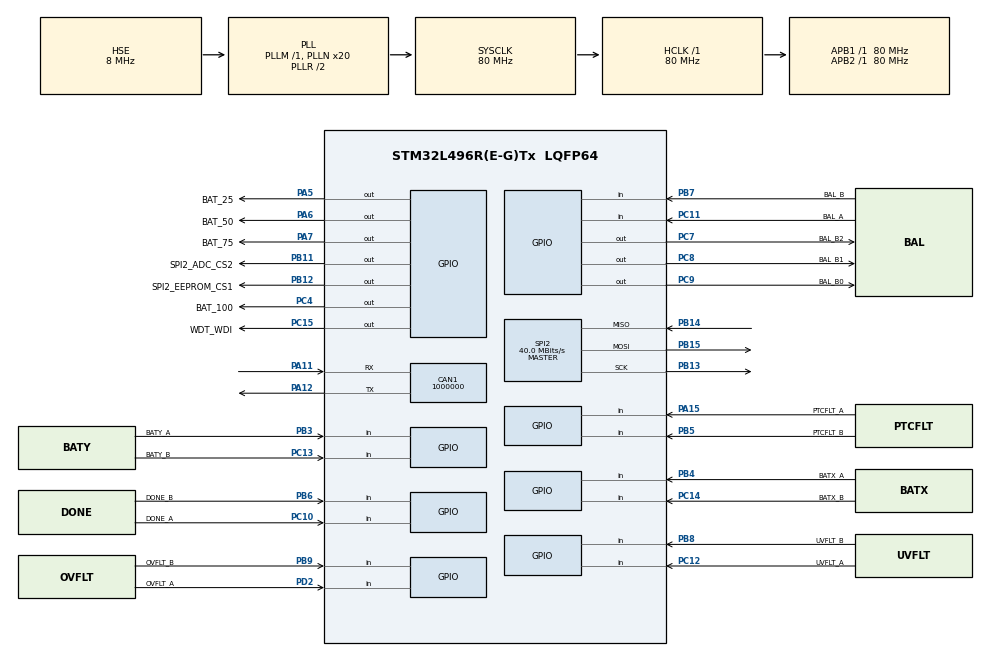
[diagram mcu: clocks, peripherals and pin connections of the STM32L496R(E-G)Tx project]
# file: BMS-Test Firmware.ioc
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CAN1.BS1=CAN_BS1_3TQ
CAN1.CalculateBaudRate=1000000
CAN1.CalculateTimeBit=1000.00
CAN1.CalculateTimeQuantum=200.0
Mcu.Family=STM32L4
Mcu.Name=STM32L496R(E-G)Tx
Mcu.Package=LQFP64
NVIC.PriorityGroup=NVIC_PRIORITYGROUP_4
PA11.Mode=CAN_Activate
PA11.Signal=CAN1_RX
PA12.Mode=CAN_Activate
PA12.Signal=CAN1_TX
PA13\ (JTMS/SWDIO).Mode=Serial_Wire
PA13\ (JTMS/SWDIO).Signal=SYS_JTMS-SWDIO
PA14\ (JTCK/SWCLK).Mode=Serial_Wire
PA14\ (JTCK/SWCLK).Signal=SYS_JTCK-SWCLK
PA15\ (JTDI).GPIO_Label=PTCFLT_A
PA15\ (JTDI).Signal=GPIO_Input
PA5.GPIO_Label=BAT_25
PA5.Signal=GPIO_Output
PA6.GPIO_Label=BAT_50
PA6.Signal=GPIO_Output
PA7.GPIO_Label=BAT_75
PA7.Signal=GPIO_Output
PB11.GPIO_Label=SPI2_ADC_CS2
PB11.Signal=GPIO_Output
PB12.GPIO_Label=SPI2_EEPROM_CS1
PB12.Signal=GPIO_Output
PB13.Mode=Full_Duplex_Master
PB13.Signal=SPI2_SCK
PB14.Mode=Full_Duplex_Master
PB14.Signal=SPI2_MISO
PB15.Mode=Full_Duplex_Master
PB15.Signal=SPI2_MOSI
PB3\ (JTDO/TRACESWO).GPIO_Label=BATY_A
PB3\ (JTDO/TRACESWO).Signal=GPIO_Input
PB4\ (NJTRST).GPIO_Label=BATX_A
PB4\ (NJTRST).Signal=GPIO_Input
PB5.GPIO_Label=PTCFLT_B
PB5.Signal=GPIO_Input
PB6.GPIO_Label=DONE_B
PB6.Signal=GPIO_Input
PB7.GPIO_Label=BAL_B
PB7.Signal=GPIO_Input
PB8.GPIO_Label=UVFLT_B
PB8.Signal=GPIO_Input
PB9.GPIO_Label=OVFLT_B
PB9.Signal=GPIO_Input
PC10.GPIO_Label=DONE_A
PC10.Signal=GPIO_Input
PC11.GPIO_Label=BAL_A
PC11.Signal=GPIO_Input
PC12.GPIO_Label=UVFLT_A
PC12.Signal=GPIO_Input
PC13.GPIO_Label=BATY_B
PC13.Signal=GPIO_Input
PC14-OSC32_IN\ (PC14).GPIO_Label=BATX_B
PC14-OSC32_IN\ (PC14).Signal=GPIO_Input
PC15-OSC32_OUT\ (PC15).GPIO_Label=WDT_WDI
PC15-OSC32_OUT\ (PC15).Signal=GPIO_Output
PC4.GPIO_Label=BAT_100
PC4.Signal=GPIO_Output
PC7.GPIO_Label=BAL_B2
PC7.Signal=GPIO_Output
PC8.GPIO_Label=BAL_B1
PC8.Signal=GPIO_Output
PC9.GPIO_Label=BAL_B0
PC9.Signal=GPIO_Output
PD2.GPIO_Label=OVFLT_A
PD2.Signal=GPIO_Input
PH0-OSC_IN\ (PH0).Mode=HSE-External-Oscillator
PH0-OSC_IN\ (PH0).Signal=RCC_OSC_IN
PH1-OSC_OUT\ (PH1).Mode=HSE-External-Oscillator
PH1-OSC_OUT\ (PH1).Signal=RCC_OSC_OUT
ProjectManager.HeapSize=0x200
ProjectManager.StackSize=0x400
ProjectManager.TargetToolchain=STM32CubeIDE
RCC.ADCFreq_Value=32000000
RCC.AHBFreq_Value=80000000
RCC.APB1Freq_Value=80000000
RCC.APB1TimFreq_Value=80000000
RCC.APB2Freq_Value=80000000
RCC.APB2TimFreq_Value=80000000
RCC.CortexFreq_Value=80000000
RCC.HCLKFreq_Value=80000000
RCC.HSE_VALUE=8000000
RCC.HSI48_VALUE=48000000
RCC.HSI_VALUE=16000000
RCC.LSE_VALUE=32768
RCC.MSI_VALUE=4000000
RCC.PLLN=20
RCC.PLLSourceVirtual=RCC_PLLSOURCE_HSE
RCC.SYSCLKFreq_VALUE=80000000
RCC.SYSCLKSource=RCC_SYSCLKSOURCE_PLLCLK
RCC.USBFreq_Value=32000000
RCC.VCOOutputFreq_Value=160000000
SPI2.CalculateBaudRate=40.0 MBits/s
SPI2.Direction=SPI_DIRECTION_2LINES
SPI2.Mode=SPI_MODE_MASTER
SPI2.VirtualNSS=VM_NSSHARD
SPI2.VirtualType=VM_MASTER
board=custom

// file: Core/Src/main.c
/* USER CODE BEGIN Header */
/**
  ******************************************************************************
  * @file           : main.c
  * @brief          : Main program body
  ******************************************************************************
  * @attention
  *
  * <h2><center>&copy; Copyright (c) 2021 STMicroelectronics.
  * All rights reserved.</center></h2>
  *
  * This software component is licensed by ST under BSD 3-Clause license,
  * the "License"; You may not use this file except in compliance with the
  * License. You may obtain a copy of the License at:
  *                        opensource.org/licenses/BSD-3-Clause
  *
  ******************************************************************************
  */
/* USER CODE END Header */
#include "main.h"
#include "can.h"
#include "spi.h"
#include "gpio.h"

void SystemClock_Config(void);

int main(void)
{

  /* MCU Configuration--------------------------------------------------------*/

  /* Reset of all peripherals, Initializes the Flash interface and the Systick. */
  HAL_Init();

  /* Configure the system clock */
  SystemClock_Config();

  /* Initialize all configured peripherals */
  MX_GPIO_Init();
  MX_CAN1_Init();
  MX_SPI2_Init();

  /* Infinite loop */
  /* USER CODE BEGIN WHILE */
  while (1)
  {
	  bal_bat_get();
	  bms_LED_update();
    /* USER CODE END WHILE */

  }
}

void SystemClock_Config(void)
{
  RCC_OscInitTypeDef RCC_OscInitStruct = {0};
  RCC_ClkInitTypeDef RCC_ClkInitStruct = {0};

  /** Configure the main internal regulator output voltage
  */
  if (HAL_PWREx_ControlVoltageScaling(PWR_REGULATOR_VOLTAGE_SCALE1) != HAL_OK)
  {
    Error_Handler();
  }
  /** Initializes the RCC Oscillators according to the specified parameters
  * in the RCC_OscInitTypeDef structure.
  */
  RCC_OscInitStruct.OscillatorType = RCC_OSCILLATORTYPE_HSE;
  RCC_OscInitStruct.HSEState = RCC_HSE_ON;
  RCC_OscInitStruct.PLL.PLLState = RCC_PLL_ON;
  RCC_OscInitStruct.PLL.PLLSource = RCC_PLLSOURCE_HSE;
  RCC_OscInitStruct.PLL.PLLM = 1;
  RCC_OscInitStruct.PLL.PLLN = 20;
  RCC_OscInitStruct.PLL.PLLP = RCC_PLLP_DIV2;
  RCC_OscInitStruct.PLL.PLLQ = RCC_PLLQ_DIV2;
  RCC_OscInitStruct.PLL.PLLR = RCC_PLLR_DIV2;
  if (HAL_RCC_OscConfig(&RCC_OscInitStruct) != HAL_OK)
  {
    Error_Handler();
  }
  /** Initializes the CPU, AHB and APB buses clocks
  */
  RCC_ClkInitStruct.ClockType = RCC_CLOCKTYPE_HCLK|RCC_CLOCKTYPE_SYSCLK
                              |RCC_CLOCKTYPE_PCLK1|RCC_CLOCKTYPE_PCLK2;
  RCC_ClkInitStruct.SYSCLKSource = RCC_SYSCLKSOURCE_PLLCLK;
  RCC_ClkInitStruct.AHBCLKDivider = RCC_SYSCLK_DIV1;
  RCC_ClkInitStruct.APB1CLKDivider = RCC_HCLK_DIV1;
  RCC_ClkInitStruct.APB2CLKDivider = RCC_HCLK_DIV1;

  if (HAL_RCC_ClockConfig(&RCC_ClkInitStruct, FLASH_LATENCY_4) != HAL_OK)
  {
    Error_Handler();
  }
}

void Error_Handler(void)
{
  __disable_irq();
  while (1)
  {
  }
}

/************************ (C) COPYRIGHT STMicroelectronics *****END OF FILE****/
